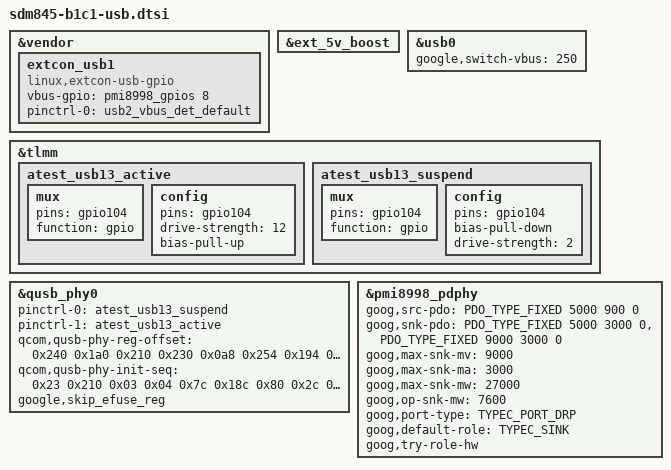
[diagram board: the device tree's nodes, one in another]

#include <dt-bindings/usb/typec.h>

&vendor {
	extcon_usb1: extcon_usb1 {
		compatible = "linux,extcon-usb-gpio";
		vbus-gpio = <&pmi8998_gpios 8 GPIO_ACTIVE_HIGH>;

		pinctrl-names = "default";
		pinctrl-0 = <&usb2_vbus_det_default>;
	};
};

&ext_5v_boost {
	status = "ok";
};

&usb0 {
	google,switch-vbus = <250>;
};

&tlmm {
	/**
	 * HS enumeration WAR: Add an external pull down resistor (1 K
	 * ~ 1.2 K to USB_DP pin via an external switch controlled by
	 * GPIO104 to enable pull down resistance needed for HS
	 * enumeration.
	 */
	atest_usb13_active: atest_usb13_active {
		mux {
			pins = "gpio104";
			function = "gpio";
		};
		config {
			pins = "gpio104";
			drive-strength = <12>;
			bias-pull-up;
		};
	};
	atest_usb13_suspend: atest_usb13_suspend {
		mux {
			pins = "gpio104";
			function = "gpio";
		};
		config {
			pins = "gpio104";
			bias-pull-down;
			drive-strength = <2>;
		};
	};
};

&qusb_phy0 {
	/* Primary USB port related QUSB2 PHY */
	pinctrl-names = "atest_usb13_suspend", "atest_usb13_active";
	pinctrl-0 = <&atest_usb13_suspend>;
	pinctrl-1 = <&atest_usb13_active>;

	qcom,qusb-phy-reg-offset =
		<0x240 /* QUSB2PHY_PORT_TUNE1 */
		 0x1a0 /* QUSB2PHY_PLL_COMMON_STATUS_ONE */
		 0x210 /* QUSB2PHY_PWR_CTRL1 */
		 0x230 /* QUSB2PHY_INTR_CTRL */
		 0x0a8 /* QUSB2PHY_PLL_CORE_INPUT_OVERRIDE */
		 0x254 /* QUSB2PHY_TEST1 */
		 0x194 /* PLL_BIAS_CONTROL_1 */
		 0x198 /* PLL_BIAS_CONTROL_2 */
		 0x228 /* QUSB2PHY_SQ_CTRL1 */
		 0x22c /* QUSB2PHY_SQ_CTRL2 */
		 0x27c>; /* QUSB2PHY_DEBUG_CTRL1 */

	qcom,qusb-phy-init-seq =
			/* <value reg_offset> */
			<0x23 0x210 /* PWR_CTRL1 */
			 0x03 0x04  /* PLL_ANALOG_CONTROLS_TWO */
			 0x7c 0x18c /* PLL_CLOCK_INVERTERS */
			 0x80 0x2c  /* PLL_CMODE */
			 0x0a 0x184 /* PLL_LOCK_DELAY */
			 0x19 0xb4  /* PLL_DIGITAL_TIMERS_TWO */
			 0x40 0x194 /* PLL_BIAS_CONTROL_1 */
			 0x20 0x198 /* PLL_BIAS_CONTROL_2 */
			 0x21 0x214 /* PWR_CTRL2 */
			 0x00 0x220 /* IMP_CTRL1 */
			 0x58 0x224 /* IMP_CTRL2 */
			 0x75 0x240 /* TUNE1 */
			 0x29 0x244 /* TUNE2 */
			 0xca 0x248 /* TUNE3 */
			 0x04 0x24c /* TUNE4 */
			 0x03 0x250 /* TUNE5 */
			 0x00 0x23c /* CHG_CTRL2 */
			 0x22 0x210>; /* PWR_CTRL1 */

	google,skip_efuse_reg;
};

&pmi8998_pdphy {
	goog,src-pdo = <PDO_TYPE_FIXED 5000 900 0>;	/* 5V @ 0.9A */
	goog,snk-pdo = <PDO_TYPE_FIXED 5000 3000 0>,	/* 5V @ 3A */
		       <PDO_TYPE_FIXED 9000 3000 0>;	/* 9V @ 3A */
	goog,max-snk-mv = <9000>;
	goog,max-snk-ma = <3000>;
	goog,max-snk-mw = <27000>;
	goog,op-snk-mw = <7600>;
	goog,port-type = <TYPEC_PORT_DRP>;
	goog,default-role = <TYPEC_SINK>;
	goog,try-role-hw;
};
